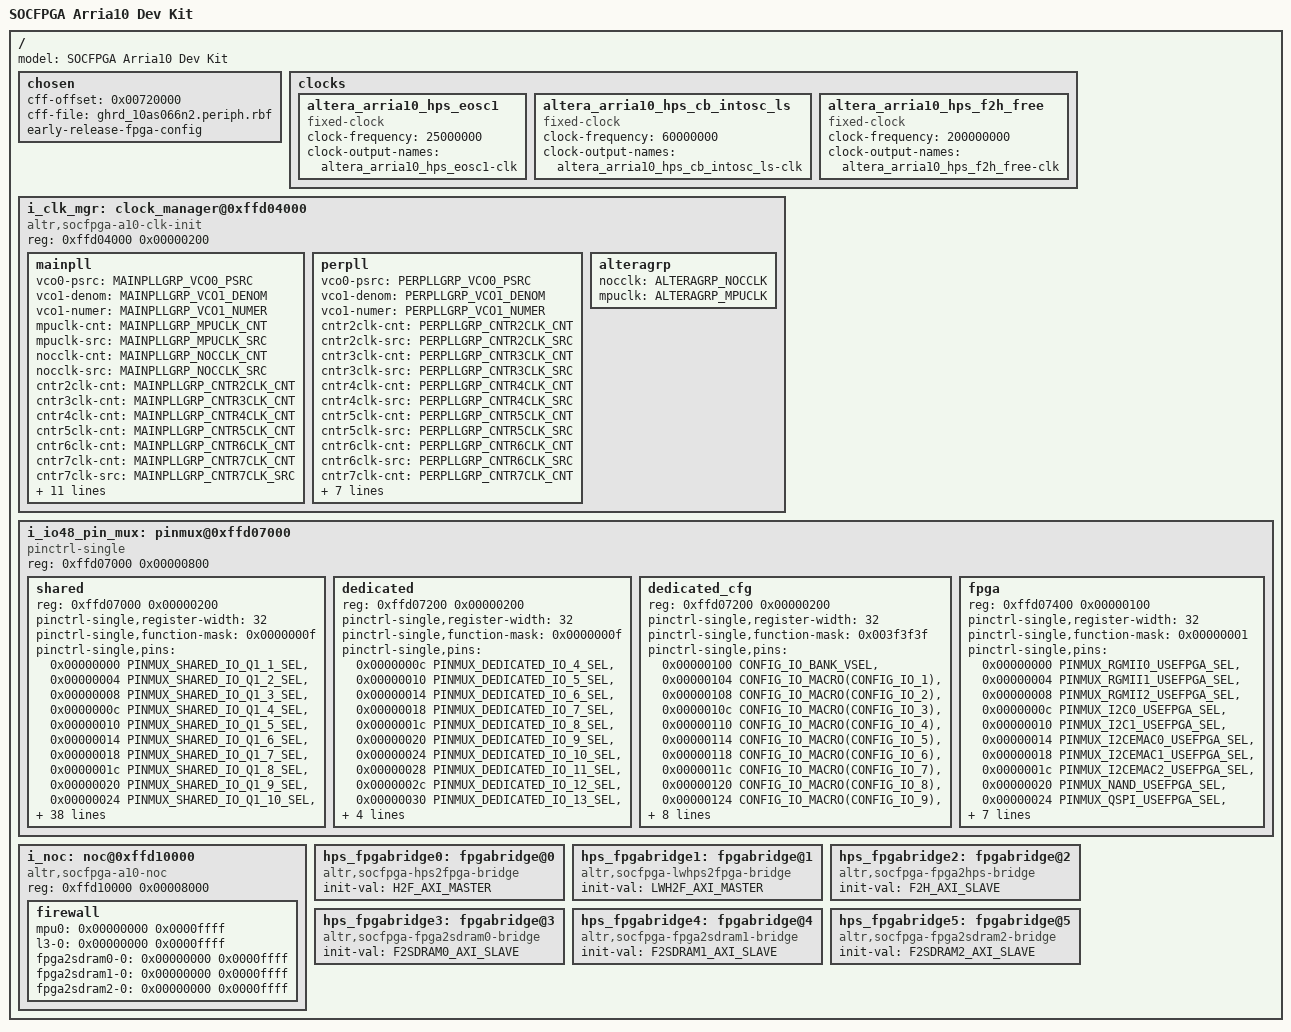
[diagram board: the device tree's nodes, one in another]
/*
 * GENERATED FILE - DO NOT EDIT
 *
 * Copyright Altera Corporation (C) 2012-2015. All rights reserved
 *
 * SPDX-License-Identifier: BSD-3-Clause License
 *
 * Redistribution and use in source and binary forms, with or without
 * modification, are permitted provided that the following conditions are met:
 *    * Redistributions of source code must retain the above copyright
 *      notice, this list of conditions and the following disclaimer.
 *    * Redistributions in binary form must reproduce the above copyright
 *      notice, this list of conditions and the following disclaimer in the
 *      documentation and/or other materials provided with the distribution.
 *    * Neither the name of Altera Corporation nor the
 *      names of its contributors may be used to endorse or promote products
 *      derived from this software without specific prior written permission.
 *
 * THIS SOFTWARE IS PROVIDED BY THE COPYRIGHT HOLDERS AND CONTRIBUTORS "AS IS" AND
 * ANY EXPRESS OR IMPLIED WARRANTIES, INCLUDING, BUT NOT LIMITED TO, THE IMPLIED
 * WARRANTIES OF MERCHANTABILITY AND FITNESS FOR A PARTICULAR PURPOSE ARE
 * DISCLAIMED. IN NO EVENT SHALL ALTERA CORPORATION BE LIABLE FOR ANY
 * DIRECT, INDIRECT, INCIDENTAL, SPECIAL, EXEMPLARY, OR CONSEQUENTIAL DAMAGES
 * (INCLUDING, BUT NOT LIMITED TO, PROCUREMENT OF SUBSTITUTE GOODS OR SERVICES;
 * LOSS OF USE, DATA, OR PROFITS; OR BUSINESS INTERRUPTION) HOWEVER CAUSED AND
 * ON ANY THEORY OF LIABILITY, WHETHER IN CONTRACT, STRICT LIABILITY, OR TORT
 * (INCLUDING NEGLIGENCE OR OTHERWISE) ARISING IN ANY WAY OUT OF THE USE OF THIS
 * SOFTWARE, EVEN IF ADVISED OF THE POSSIBILITY OF SUCH DAMAGE.
 */

/dts-v1/;

#include "Arria10Handoff.h"


/*
 * Bootloader: uefi
 * Version: 1.0
 */
/ {
	#address-cells = <1>;
	#size-cells = <1>;
	model = "SOCFPGA Arria10 Dev Kit";	/* Bootloader setting: uefi.model */

	chosen {
		cff-offset = <0x00720000>;	/* Bootloader setting: uefi.rbf_offset */
		cff-file = "ghrd_10as066n2.periph.rbf"; /* Bootloader setting: uefi.rbf_filename */
		early-release-fpga-config;
	};

	/* Clock sources */
	clocks {
		#address-cells = <1>;
		#size-cells = <1>;

		/* Clock source: altera_arria10_hps_eosc1 */
		altera_arria10_hps_eosc1: altera_arria10_hps_eosc1 {
			compatible = "fixed-clock";
			#clock-cells = <0>;
			clock-frequency = <25000000>;
			clock-output-names = "altera_arria10_hps_eosc1-clk";
		};

		/* Clock source: altera_arria10_hps_cb_intosc_ls */
		altera_arria10_hps_cb_intosc_ls: altera_arria10_hps_cb_intosc_ls {
			compatible = "fixed-clock";
			#clock-cells = <0>;
			clock-frequency = <60000000>;
			clock-output-names = "altera_arria10_hps_cb_intosc_ls-clk";
		};

		/* Clock source: altera_arria10_hps_f2h_free */
		altera_arria10_hps_f2h_free: altera_arria10_hps_f2h_free {
			compatible = "fixed-clock";
			#clock-cells = <0>;
			clock-frequency = <200000000>;
			clock-output-names = "altera_arria10_hps_f2h_free-clk";
		};
	};

	/*
	 * Driver: altera_arria10_soc_clock_manager_arria10_uefi_driver
	 * Version: 1.0
	 * Binding: device
	 */
	i_clk_mgr: clock_manager@0xffd04000 {
		compatible = "altr,socfpga-a10-clk-init";
		reg = <0xffd04000 0x00000200>;
		reg-names = "soc_clock_manager_OCP_SLV";

		/* Address Block: soc_clock_manager_OCP_SLV.i_clk_mgr_mainpllgrp */
		mainpll {
			vco0-psrc = <MAINPLLGRP_VCO0_PSRC>;	/* Field: vco0.psrc */
			vco1-denom = <MAINPLLGRP_VCO1_DENOM>;	/* Field: vco1.denom */
			vco1-numer = <MAINPLLGRP_VCO1_NUMER>;	/* Field: vco1.numer */
			mpuclk-cnt = <MAINPLLGRP_MPUCLK_CNT>;	/* Field: mpuclk.cnt */
			mpuclk-src = <MAINPLLGRP_MPUCLK_SRC>;	/* Field: mpuclk.src */
			nocclk-cnt = <MAINPLLGRP_NOCCLK_CNT>;	/* Field: nocclk.cnt */
			nocclk-src = <MAINPLLGRP_NOCCLK_SRC>;	/* Field: nocclk.src */
			cntr2clk-cnt = <MAINPLLGRP_CNTR2CLK_CNT>;/* Field: cntr2clk.cnt */
			cntr3clk-cnt = <MAINPLLGRP_CNTR3CLK_CNT>;	/* Field: cntr3clk.cnt */
			cntr4clk-cnt = <MAINPLLGRP_CNTR4CLK_CNT>;	/* Field: cntr4clk.cnt */
			cntr5clk-cnt = <MAINPLLGRP_CNTR5CLK_CNT>;	/* Field: cntr5clk.cnt */
			cntr6clk-cnt = <MAINPLLGRP_CNTR6CLK_CNT>;	/* Field: cntr6clk.cnt */
			cntr7clk-cnt = <MAINPLLGRP_CNTR7CLK_CNT>;	/* Field: cntr7clk.cnt */
			cntr7clk-src = <MAINPLLGRP_CNTR7CLK_SRC>;	/* Field: cntr7clk.src */
			cntr8clk-cnt = <MAINPLLGRP_CNTR8CLK_CNT>;	/* Field: cntr8clk.cnt */
			cntr9clk-cnt = <MAINPLLGRP_CNTR9CLK_CNT>;	/* Field: cntr9clk.cnt */
			cntr9clk-src = <MAINPLLGRP_CNTR9CLK_SRC>;	/* Field: cntr9clk.src */
			cntr15clk-cnt = <MAINPLLGRP_CNTR15CLK_CNT>;	/* Field: cntr15clk.cnt */
			nocdiv-l4mainclk = <MAINPLLGRP_NOCDIV_L4MAINCLK>;	/* Field: nocdiv.l4mainclk */
			nocdiv-l4mpclk = <MAINPLLGRP_NOCDIV_L4MPCLK>;	/* Field: nocdiv.l4mpclk */
			nocdiv-l4spclk = <MAINPLLGRP_NOCDIV_L4SPCLK>;	/* Field: nocdiv.l4spclk */
			nocdiv-csatclk = <MAINPLLGRP_NOCDIV_CSATCLK>;	/* Field: nocdiv.csatclk */
			nocdiv-cstraceclk = <MAINPLLGRP_NOCDIV_CSTRACECLK>;	/* Field: nocdiv.cstraceclk */
			nocdiv-cspdbgclk = <MAINPLLGRP_NOCDIV_CSPDBGCLK>;	/* Field: nocdiv.cspdbgclk */
		};

		/* Address Block: soc_clock_manager_OCP_SLV.i_clk_mgr_perpllgrp */
		perpll {
			vco0-psrc = <PERPLLGRP_VCO0_PSRC>;	/* Field: vco0.psrc */
			vco1-denom = <PERPLLGRP_VCO1_DENOM>;	/* Field: vco1.denom */
			vco1-numer = <PERPLLGRP_VCO1_NUMER>;	/* Field: vco1.numer */
			cntr2clk-cnt = <PERPLLGRP_CNTR2CLK_CNT>;	/* Field: cntr2clk.cnt */
			cntr2clk-src = <PERPLLGRP_CNTR2CLK_SRC>;	/* Field: cntr2clk.src */
			cntr3clk-cnt = <PERPLLGRP_CNTR3CLK_CNT>;	/* Field: cntr3clk.cnt */
			cntr3clk-src = <PERPLLGRP_CNTR3CLK_SRC>;	/* Field: cntr3clk.src */
			cntr4clk-cnt = <PERPLLGRP_CNTR4CLK_CNT>;	/* Field: cntr4clk.cnt */
			cntr4clk-src = <PERPLLGRP_CNTR4CLK_SRC>;	/* Field: cntr4clk.src */
			cntr5clk-cnt = <PERPLLGRP_CNTR5CLK_CNT>;	/* Field: cntr5clk.cnt */
			cntr5clk-src = <PERPLLGRP_CNTR5CLK_SRC>;	/* Field: cntr5clk.src */
			cntr6clk-cnt = <PERPLLGRP_CNTR6CLK_CNT>;	/* Field: cntr6clk.cnt */
			cntr6clk-src = <PERPLLGRP_CNTR6CLK_SRC>;	/* Field: cntr6clk.src */
			cntr7clk-cnt = <PERPLLGRP_CNTR7CLK_CNT>;	/* Field: cntr7clk.cnt */
			cntr8clk-cnt = <PERPLLGRP_CNTR8CLK_CNT>;	/* Field: cntr8clk.cnt */
			cntr8clk-src = <PERPLLGRP_CNTR8CLK_SRC>;	/* Field: cntr8clk.src */
			cntr9clk-cnt = <PERPLLGRP_CNTR9CLK_CNT>;	/* Field: cntr9clk.cnt */
			emacctl-emac0sel = <PERPLLGRP_EMACCTL_EMAC0SEL>;	/* Field: emacctl.emac0sel */
			emacctl-emac1sel = <PERPLLGRP_EMACCTL_EMAC1SEL>;	/* Field: emacctl.emac1sel */
			emacctl-emac2sel = <PERPLLGRP_EMACCTL_EMAC2SEL>;	/* Field: emacctl.emac2sel */
			gpiodiv-gpiodbclk = <PERPLLGRP_GPIODIV_GPIODBCLK>;	/* Field: gpiodiv.gpiodbclk */
		};

		/* Address Block: soc_clock_manager_OCP_SLV.i_clk_mgr_alteragrp */
		alteragrp {
			nocclk = <ALTERAGRP_NOCCLK>;	/* Register: nocclk */
			mpuclk = <ALTERAGRP_MPUCLK>;	/* Register: mpuclk */
		};
	};

	/*
	 * Driver: altera_arria10_soc_3v_io48_pin_mux_arria10_uefi_driver
	 * Version: 1.0
	 * Binding: pinmux
	 */
	i_io48_pin_mux: pinmux@0xffd07000 {
		#address-cells = <1>;
		#size-cells = <1>;
		compatible = "pinctrl-single";
		reg = <0xffd07000 0x00000800>;
		reg-names = "soc_3v_io48_pin_mux_OCP_SLV";

		/* Address Block: soc_3v_io48_pin_mux_OCP_SLV.i_io48_pin_mux_shared_3v_io_grp */
		shared {
			reg = <0xffd07000 0x00000200>;
			pinctrl-single,register-width = <32>;
			pinctrl-single,function-mask = <0x0000000f>;
			pinctrl-single,pins =
				<0x00000000 PINMUX_SHARED_IO_Q1_1_SEL>,	/* Register: pinmux_shared_io_q1_1 */
				<0x00000004 PINMUX_SHARED_IO_Q1_2_SEL>,	/* Register: pinmux_shared_io_q1_2 */
				<0x00000008 PINMUX_SHARED_IO_Q1_3_SEL>,	/* Register: pinmux_shared_io_q1_3 */
				<0x0000000c PINMUX_SHARED_IO_Q1_4_SEL>,	/* Register: pinmux_shared_io_q1_4 */
				<0x00000010 PINMUX_SHARED_IO_Q1_5_SEL>,	/* Register: pinmux_shared_io_q1_5 */
				<0x00000014 PINMUX_SHARED_IO_Q1_6_SEL>,	/* Register: pinmux_shared_io_q1_6 */
				<0x00000018 PINMUX_SHARED_IO_Q1_7_SEL>,	/* Register: pinmux_shared_io_q1_7 */
				<0x0000001c PINMUX_SHARED_IO_Q1_8_SEL>,	/* Register: pinmux_shared_io_q1_8 */
				<0x00000020 PINMUX_SHARED_IO_Q1_9_SEL>,	/* Register: pinmux_shared_io_q1_9 */
				<0x00000024 PINMUX_SHARED_IO_Q1_10_SEL>,	/* Register: pinmux_shared_io_q1_10 */
				<0x00000028 PINMUX_SHARED_IO_Q1_11_SEL>,	/* Register: pinmux_shared_io_q1_11 */
				<0x0000002c PINMUX_SHARED_IO_Q1_12_SEL>,	/* Register: pinmux_shared_io_q1_12 */
				<0x00000030 PINMUX_SHARED_IO_Q2_1_SEL>,	/* Register: pinmux_shared_io_q2_1 */
				<0x00000034 PINMUX_SHARED_IO_Q2_2_SEL>,	/* Register: pinmux_shared_io_q2_2 */
				<0x00000038 PINMUX_SHARED_IO_Q2_3_SEL>,	/* Register: pinmux_shared_io_q2_3 */
				<0x0000003c PINMUX_SHARED_IO_Q2_4_SEL>,	/* Register: pinmux_shared_io_q2_4 */
				<0x00000040 PINMUX_SHARED_IO_Q2_5_SEL>,	/* Register: pinmux_shared_io_q2_5 */
				<0x00000044 PINMUX_SHARED_IO_Q2_6_SEL>,	/* Register: pinmux_shared_io_q2_6 */
				<0x00000048 PINMUX_SHARED_IO_Q2_7_SEL>,	/* Register: pinmux_shared_io_q2_7 */
				<0x0000004c PINMUX_SHARED_IO_Q2_8_SEL>,	/* Register: pinmux_shared_io_q2_8 */
				<0x00000050 PINMUX_SHARED_IO_Q2_9_SEL>,	/* Register: pinmux_shared_io_q2_9 */
				<0x00000054 PINMUX_SHARED_IO_Q2_10_SEL>,	/* Register: pinmux_shared_io_q2_10 */
				<0x00000058 PINMUX_SHARED_IO_Q2_11_SEL>,	/* Register: pinmux_shared_io_q2_11 */
				<0x0000005c PINMUX_SHARED_IO_Q2_12_SEL>,	/* Register: pinmux_shared_io_q2_12 */
				<0x00000060 PINMUX_SHARED_IO_Q3_1_SEL>,	/* Register: pinmux_shared_io_q3_1 */
				<0x00000064 PINMUX_SHARED_IO_Q3_2_SEL>,	/* Register: pinmux_shared_io_q3_2 */
				<0x00000068 PINMUX_SHARED_IO_Q3_3_SEL>,	/* Register: pinmux_shared_io_q3_3 */
				<0x0000006c PINMUX_SHARED_IO_Q3_4_SEL>,	/* Register: pinmux_shared_io_q3_4 */
				<0x00000070 PINMUX_SHARED_IO_Q3_5_SEL>,	/* Register: pinmux_shared_io_q3_5 */
				<0x00000074 PINMUX_SHARED_IO_Q3_6_SEL>,	/* Register: pinmux_shared_io_q3_6 */
				<0x00000078 PINMUX_SHARED_IO_Q3_7_SEL>,	/* Register: pinmux_shared_io_q3_7 */
				<0x0000007c PINMUX_SHARED_IO_Q3_8_SEL>,	/* Register: pinmux_shared_io_q3_8 */
				<0x00000080 PINMUX_SHARED_IO_Q3_9_SEL>,	/* Register: pinmux_shared_io_q3_9 */
				<0x00000084 PINMUX_SHARED_IO_Q3_10_SEL>,	/* Register: pinmux_shared_io_q3_10 */
				<0x00000088 PINMUX_SHARED_IO_Q3_11_SEL>,	/* Register: pinmux_shared_io_q3_11 */
				<0x0000008c PINMUX_SHARED_IO_Q3_12_SEL>,	/* Register: pinmux_shared_io_q3_12 */
				<0x00000090 PINMUX_SHARED_IO_Q4_1_SEL>,	/* Register: pinmux_shared_io_q4_1 */
				<0x00000094 PINMUX_SHARED_IO_Q4_2_SEL>,	/* Register: pinmux_shared_io_q4_2 */
				<0x00000098 PINMUX_SHARED_IO_Q4_3_SEL>,	/* Register: pinmux_shared_io_q4_3 */
				<0x0000009c PINMUX_SHARED_IO_Q4_4_SEL>,	/* Register: pinmux_shared_io_q4_4 */
				<0x000000a0 PINMUX_SHARED_IO_Q4_5_SEL>,	/* Register: pinmux_shared_io_q4_5 */
				<0x000000a4 PINMUX_SHARED_IO_Q4_6_SEL>,	/* Register: pinmux_shared_io_q4_6 */
				<0x000000a8 PINMUX_SHARED_IO_Q4_7_SEL>,	/* Register: pinmux_shared_io_q4_7 */
				<0x000000ac PINMUX_SHARED_IO_Q4_8_SEL>,	/* Register: pinmux_shared_io_q4_8 */
				<0x000000b0 PINMUX_SHARED_IO_Q4_9_SEL>,	/* Register: pinmux_shared_io_q4_9 */
				<0x000000b4 PINMUX_SHARED_IO_Q4_10_SEL>,	/* Register: pinmux_shared_io_q4_10 */
				<0x000000b8 PINMUX_SHARED_IO_Q4_11_SEL>,	/* Register: pinmux_shared_io_q4_11 */
				<0x000000bc PINMUX_SHARED_IO_Q4_12_SEL>;	/* Register: pinmux_shared_io_q4_12 */
		};

		/* Address Block: soc_3v_io48_pin_mux_OCP_SLV.i_io48_pin_mux_dedicated_io_grp */
		dedicated {
			reg = <0xffd07200 0x00000200>;
			pinctrl-single,register-width = <32>;
			pinctrl-single,function-mask = <0x0000000f>;
			pinctrl-single,pins =
				<0x0000000c PINMUX_DEDICATED_IO_4_SEL>,	/* Register: pinmux_dedicated_io_4 */
				<0x00000010 PINMUX_DEDICATED_IO_5_SEL>,	/* Register: pinmux_dedicated_io_5 */
				<0x00000014 PINMUX_DEDICATED_IO_6_SEL>,	/* Register: pinmux_dedicated_io_6 */
				<0x00000018 PINMUX_DEDICATED_IO_7_SEL>,	/* Register: pinmux_dedicated_io_7 */
				<0x0000001c PINMUX_DEDICATED_IO_8_SEL>,	/* Register: pinmux_dedicated_io_8 */
				<0x00000020 PINMUX_DEDICATED_IO_9_SEL>,	/* Register: pinmux_dedicated_io_9 */
				<0x00000024 PINMUX_DEDICATED_IO_10_SEL>,	/* Register: pinmux_dedicated_io_10 */
				<0x00000028 PINMUX_DEDICATED_IO_11_SEL>,	/* Register: pinmux_dedicated_io_11 */
				<0x0000002c PINMUX_DEDICATED_IO_12_SEL>,	/* Register: pinmux_dedicated_io_12 */
				<0x00000030 PINMUX_DEDICATED_IO_13_SEL>,	/* Register: pinmux_dedicated_io_13 */
				<0x00000034 PINMUX_DEDICATED_IO_14_SEL>,	/* Register: pinmux_dedicated_io_14 */
				<0x00000038 PINMUX_DEDICATED_IO_15_SEL>,	/* Register: pinmux_dedicated_io_15 */
				<0x0000003c PINMUX_DEDICATED_IO_16_SEL>,	/* Register: pinmux_dedicated_io_16 */
				<0x00000040 PINMUX_DEDICATED_IO_17_SEL>;	/* Register: pinmux_dedicated_io_17 */
		};

		/* Address Block: soc_3v_io48_pin_mux_OCP_SLV.i_io48_pin_mux_dedicated_io_grp */
		dedicated_cfg {
			reg = <0xffd07200 0x00000200>;
			pinctrl-single,register-width = <32>;
			pinctrl-single,function-mask = <0x003f3f3f>;
			pinctrl-single,pins =
				<0x00000100 CONFIG_IO_BANK_VSEL>,	/* Register: configuration_dedicated_io_bank */
				<0x00000104 CONFIG_IO_MACRO(CONFIG_IO_1)>,	/* Register: configuration_dedicated_io_1 */
				<0x00000108 CONFIG_IO_MACRO(CONFIG_IO_2)>,	/* Register: configuration_dedicated_io_2 */
				<0x0000010c CONFIG_IO_MACRO(CONFIG_IO_3)>,	/* Register: configuration_dedicated_io_3 */
				<0x00000110 CONFIG_IO_MACRO(CONFIG_IO_4)>,	/* Register: configuration_dedicated_io_4 */
				<0x00000114 CONFIG_IO_MACRO(CONFIG_IO_5)>,	/* Register: configuration_dedicated_io_5 */
				<0x00000118 CONFIG_IO_MACRO(CONFIG_IO_6)>,	/* Register: configuration_dedicated_io_6 */
				<0x0000011c CONFIG_IO_MACRO(CONFIG_IO_7)>,	/* Register: configuration_dedicated_io_7 */
				<0x00000120 CONFIG_IO_MACRO(CONFIG_IO_8)>,	/* Register: configuration_dedicated_io_8 */
				<0x00000124 CONFIG_IO_MACRO(CONFIG_IO_9)>,	/* Register: configuration_dedicated_io_9 */
				<0x00000128 CONFIG_IO_MACRO(CONFIG_IO_10)>,	/* Register: configuration_dedicated_io_10 */
				<0x0000012c CONFIG_IO_MACRO(CONFIG_IO_11)>,	/* Register: configuration_dedicated_io_11 */
				<0x00000130 CONFIG_IO_MACRO(CONFIG_IO_12)>,	/* Register: configuration_dedicated_io_12 */
				<0x00000134 CONFIG_IO_MACRO(CONFIG_IO_13)>,	/* Register: configuration_dedicated_io_13 */
				<0x00000138 CONFIG_IO_MACRO(CONFIG_IO_14)>,	/* Register: configuration_dedicated_io_14 */
				<0x0000013c CONFIG_IO_MACRO(CONFIG_IO_15)>,	/* Register: configuration_dedicated_io_15 */
				<0x00000140 CONFIG_IO_MACRO(CONFIG_IO_16)>,	/* Register: configuration_dedicated_io_16 */
				<0x00000144 CONFIG_IO_MACRO(CONFIG_IO_17)>;	/* Register: configuration_dedicated_io_17 */
		};

		/* Address Block: soc_3v_io48_pin_mux_OCP_SLV.i_io48_pin_mux_fpga_interface_grp */
		fpga {
			reg = <0xffd07400 0x00000100>;
			pinctrl-single,register-width = <32>;
			pinctrl-single,function-mask = <0x00000001>;
			pinctrl-single,pins =
				<0x00000000 PINMUX_RGMII0_USEFPGA_SEL>,	/* Register: pinmux_emac0_usefpga */
				<0x00000004 PINMUX_RGMII1_USEFPGA_SEL>,	/* Register: pinmux_emac1_usefpga */
				<0x00000008 PINMUX_RGMII2_USEFPGA_SEL>,	/* Register: pinmux_emac2_usefpga */
				<0x0000000c PINMUX_I2C0_USEFPGA_SEL>,	/* Register: pinmux_i2c0_usefpga */
				<0x00000010 PINMUX_I2C1_USEFPGA_SEL>,	/* Register: pinmux_i2c1_usefpga */
				<0x00000014 PINMUX_I2CEMAC0_USEFPGA_SEL>,	/* Register: pinmux_i2c_emac0_usefpga */
				<0x00000018 PINMUX_I2CEMAC1_USEFPGA_SEL>,	/* Register: pinmux_i2c_emac1_usefpga */
				<0x0000001c PINMUX_I2CEMAC2_USEFPGA_SEL>,	/* Register: pinmux_i2c_emac2_usefpga */
				<0x00000020 PINMUX_NAND_USEFPGA_SEL>,	/* Register: pinmux_nand_usefpga */
				<0x00000024 PINMUX_QSPI_USEFPGA_SEL>,	/* Register: pinmux_qspi_usefpga */
				<0x00000028 PINMUX_SDMMC_USEFPGA_SEL>,	/* Register: pinmux_sdmmc_usefpga */
				<0x0000002c PINMUX_SPIM0_USEFPGA_SEL>,	/* Register: pinmux_spim0_usefpga */
				<0x00000030 PINMUX_SPIM1_USEFPGA_SEL>,	/* Register: pinmux_spim1_usefpga */
				<0x00000034 PINMUX_SPIS0_USEFPGA_SEL>,	/* Register: pinmux_spis0_usefpga */
				<0x00000038 PINMUX_SPIS1_USEFPGA_SEL>,	/* Register: pinmux_spis1_usefpga */
				<0x0000003c PINMUX_UART0_USEFPGA_SEL>,	/* Register: pinmux_uart0_usefpga */
				<0x00000040 PINMUX_UART1_USEFPGA_SEL>;	/* Register: pinmux_uart1_usefpga */
		};
	};

	/*
	 * Driver: altera_arria10_soc_noc_arria10_uefi_driver
	 * Version: 1.0
	 * Binding: device
	 */
	i_noc: noc@0xffd10000 {
		compatible = "altr,socfpga-a10-noc";
		reg = <0xffd10000 0x00008000>;
		reg-names = "mpu_m0";

		firewall {
			/*
			 * Driver setting: altera_arria10_soc_noc_arria10_uefi_driver.I_NOC.mpu_m0.noc_fw_ddr_mpu_fpga2sdram_ddr_scr.mpuregion0addr.base
			 * Driver setting: altera_arria10_soc_noc_arria10_uefi_driver.I_NOC.mpu_m0.noc_fw_ddr_mpu_fpga2sdram_ddr_scr.mpuregion0addr.limit
			 */
			mpu0 = <0x00000000 0x0000ffff>;
			/*
			 * Driver setting: altera_arria10_soc_noc_arria10_uefi_driver.I_NOC.mpu_m0.noc_fw_ddr_l3_ddr_scr.hpsregion0addr.base
			 * Driver setting: altera_arria10_soc_noc_arria10_uefi_driver.I_NOC.mpu_m0.noc_fw_ddr_l3_ddr_scr.hpsregion0addr.limit
			 */
			l3-0 = <0x00000000 0x0000ffff>;
			/*
			 * Driver setting: altera_arria10_soc_noc_arria10_uefi_driver.I_NOC.mpu_m0.noc_fw_ddr_mpu_fpga2sdram_ddr_scr.fpga2sdram0region0addr.base
			 * Driver setting: altera_arria10_soc_noc_arria10_uefi_driver.I_NOC.mpu_m0.noc_fw_ddr_mpu_fpga2sdram_ddr_scr.fpga2sdram0region0addr.limit
			 */
			fpga2sdram0-0 = <0x00000000 0x0000ffff>;
			/*
			 * Driver setting: altera_arria10_soc_noc_arria10_uefi_driver.I_NOC.mpu_m0.noc_fw_ddr_mpu_fpga2sdram_ddr_scr.fpga2sdram1region0addr.base
			 * Driver setting: altera_arria10_soc_noc_arria10_uefi_driver.I_NOC.mpu_m0.noc_fw_ddr_mpu_fpga2sdram_ddr_scr.fpga2sdram1region0addr.limit
			 */
			fpga2sdram1-0 = <0x00000000 0x0000ffff>;
			/*
			 * Driver setting: altera_arria10_soc_noc_arria10_uefi_driver.I_NOC.mpu_m0.noc_fw_ddr_mpu_fpga2sdram_ddr_scr.fpga2sdram2region0addr.base
			 * Driver setting: altera_arria10_soc_noc_arria10_uefi_driver.I_NOC.mpu_m0.noc_fw_ddr_mpu_fpga2sdram_ddr_scr.fpga2sdram2region0addr.limit
			 */
			fpga2sdram2-0 = <0x00000000 0x0000ffff>;
		};
	};

	hps_fpgabridge0: fpgabridge@0 {
		compatible = "altr,socfpga-hps2fpga-bridge";
		init-val = <H2F_AXI_MASTER>;
	};

	hps_fpgabridge1: fpgabridge@1 {
		compatible = "altr,socfpga-lwhps2fpga-bridge";
		init-val = <LWH2F_AXI_MASTER>;
	};

	hps_fpgabridge2: fpgabridge@2 {
		compatible = "altr,socfpga-fpga2hps-bridge";
		init-val = <F2H_AXI_SLAVE>;
	};

	hps_fpgabridge3: fpgabridge@3 {
		compatible = "altr,socfpga-fpga2sdram0-bridge";
		init-val = <F2SDRAM0_AXI_SLAVE>;
	};

	hps_fpgabridge4: fpgabridge@4 {
		compatible = "altr,socfpga-fpga2sdram1-bridge";
		init-val = <F2SDRAM1_AXI_SLAVE>;
	};

	hps_fpgabridge5: fpgabridge@5 {
		compatible = "altr,socfpga-fpga2sdram2-bridge";
		init-val = <F2SDRAM2_AXI_SLAVE>;
	};
};
